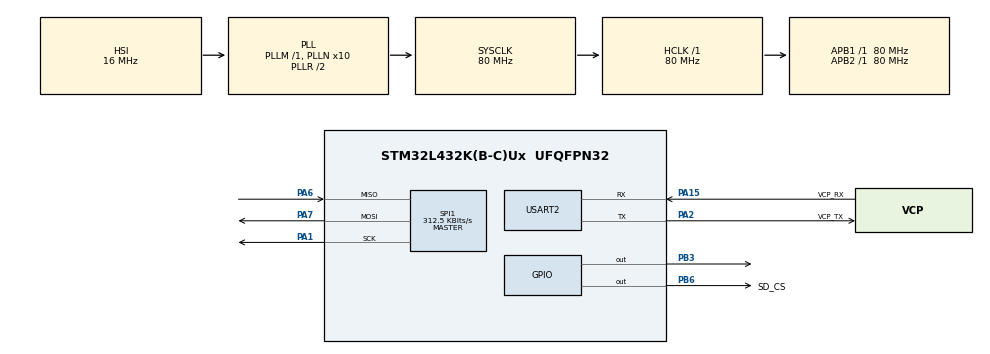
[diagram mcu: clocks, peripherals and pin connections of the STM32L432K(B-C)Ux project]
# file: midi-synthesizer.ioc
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Mcu.Family=STM32L4
Mcu.Name=STM32L432K(B-C)Ux
Mcu.Package=UFQFPN32
NUCLEO-L432KC.Bsp_Common_DEMO=true
NUCLEO-L432KC.LD3=true
NVIC.PriorityGroup=NVIC_PRIORITYGROUP_4
PA0.GPIO_Label=MCO [High speed clock in]
PA0.Signal=RCC_CK_IN
PA1.Mode=Full_Duplex_Master
PA1.Signal=SPI1_SCK
PA13\ (JTMS-SWDIO).GPIO_Label=SWDIO
PA13\ (JTMS-SWDIO).Signal=SYS_JTMS-SWDIO
PA14\ (JTCK-SWCLK).GPIO_Label=SWCLK
PA14\ (JTCK-SWCLK).Signal=SYS_JTCK-SWCLK
PA15\ (JTDI).GPIO_Label=VCP_RX
PA15\ (JTDI).Mode=Asynchronous
PA15\ (JTDI).Signal=USART2_RX
PA2.GPIO_Label=VCP_TX
PA2.Mode=Asynchronous
PA2.Signal=USART2_TX
PA6.Mode=Full_Duplex_Master
PA6.Signal=SPI1_MISO
PA7.Mode=Full_Duplex_Master
PA7.Signal=SPI1_MOSI
PB3\ (JTDO-TRACESWO).Signal=GPIO_Output
PB6.GPIO_Label=SD_CS
PB6.Signal=GPIO_Output
PC14-OSC32_IN\ (PC14).Signal=RCC_OSC32_IN
PC15-OSC32_OUT\ (PC15).Signal=RCC_OSC32_OUT
ProjectManager.HeapSize=0x200
ProjectManager.StackSize=0x400
ProjectManager.TargetToolchain=CMake
RCC.ADCFreq_Value=80000000
RCC.AHBFreq_Value=80000000
RCC.APB1Freq_Value=80000000
RCC.APB1TimFreq_Value=80000000
RCC.APB2Freq_Value=80000000
RCC.APB2TimFreq_Value=80000000
RCC.CortexFreq_Value=80000000
RCC.HCLKFreq_Value=80000000
RCC.HSE_VALUE=8000000
RCC.HSI16_VALUE=16000000
RCC.HSI48_VALUE=48000000
RCC.HSI_VALUE=16000000
RCC.LSE_VALUE=32768
RCC.MSI_VALUE=4000000
RCC.PLLMUL=RCC_PLLMUL_4
RCC.PLLN=10
RCC.PLLSAI1N=10
RCC.PLLSourceVirtual=RCC_PLLSOURCE_HSI
RCC.SYSCLKFreq_VALUE=80000000
RCC.SYSCLKSource=RCC_SYSCLKSOURCE_PLLCLK
RCC.USBFreq_Value=80000000
RCC.VCOOutputFreq_Value=160000000
SPI1.BaudRatePrescaler=SPI_BAUDRATEPRESCALER_256
SPI1.CalculateBaudRate=312.5 KBits/s
SPI1.DataSize=SPI_DATASIZE_8BIT
SPI1.Direction=SPI_DIRECTION_2LINES
SPI1.Mode=SPI_MODE_MASTER
SPI1.VirtualType=VM_MASTER
USART2.VirtualMode-Asynchronous=VM_ASYNC
VP_FATFS_VS_Generic.Mode=User_defined
VP_NUCLEO-L432KC_VS_BSP_COMMON.Mode=COMMON
board=NUCLEO-L432KC

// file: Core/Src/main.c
/* USER CODE BEGIN Header */
/**
  ******************************************************************************
  * @file           : main.c
  * @brief          : Main program body
  ******************************************************************************
  * @attention
  *
  * Copyright (c) 2026 STMicroelectronics.
  * All rights reserved.
  *
  * This software is licensed under terms that can be found in the LICENSE file
  * in the root directory of this software component.
  * If no LICENSE file comes with this software, it is provided AS-IS.
  *
  ******************************************************************************
  */
/* USER CODE END Header */
#include "main.h"
#include "fatfs.h"
#include "spi.h"
#include "usart.h"
#include "gpio.h"

/* USER CODE BEGIN Includes */
#include "SEGGER_RTT.h"
#include <stdio.h>
/* USER CODE END Includes */

void SystemClock_Config(void);

int main(void)
{

  /* MCU Configuration--------------------------------------------------------*/

  /* Reset of all peripherals, Initializes the Flash interface and the Systick. */
  HAL_Init();

  /* Configure the system clock */
  SystemClock_Config();

  /* Initialize all configured peripherals */
  MX_GPIO_Init();
  MX_SPI1_Init();
  MX_FATFS_Init();
  MX_USART2_UART_Init();
  /* USER CODE BEGIN 2 */
  SEGGER_RTT_Init();

  // Open FAT filesystem
  FATFS FatFs; //Fatfs handle
  FRESULT res;

  while ((res = f_mount(&FatFs, "", 1)) != FR_OK) { // 1=mount now
    fprintf(stderr, "f_mount error (%i)\r\n", res);
    HAL_Delay(100);
  }
  /* USER CODE END 2 */

  /* Initialize leds */
  BSP_LED_Init(LED_GREEN);

  /* USER CODE BEGIN BSP */

  /* -- Sample board code to switch on leds ---- */
  BSP_LED_On(LED_GREEN);

  /* USER CODE END BSP */

  /* Infinite loop */
  /* USER CODE BEGIN WHILE */
  while (1) {

    /* -- Sample board code to toggle leds ---- */
    BSP_LED_Toggle(LED_GREEN);

    /* USER CODE END WHILE */

  }
}

void SystemClock_Config(void)
{
  RCC_OscInitTypeDef RCC_OscInitStruct = {0};
  RCC_ClkInitTypeDef RCC_ClkInitStruct = {0};

  /** Configure the main internal regulator output voltage
  */
  if (HAL_PWREx_ControlVoltageScaling(PWR_REGULATOR_VOLTAGE_SCALE1) != HAL_OK)
  {
    Error_Handler();
  }

  /** Initializes the RCC Oscillators according to the specified parameters
  * in the RCC_OscInitTypeDef structure.
  */
  RCC_OscInitStruct.OscillatorType = RCC_OSCILLATORTYPE_HSI;
  RCC_OscInitStruct.HSIState = RCC_HSI_ON;
  RCC_OscInitStruct.HSICalibrationValue = RCC_HSICALIBRATION_DEFAULT;
  RCC_OscInitStruct.PLL.PLLState = RCC_PLL_ON;
  RCC_OscInitStruct.PLL.PLLSource = RCC_PLLSOURCE_HSI;
  RCC_OscInitStruct.PLL.PLLM = 1;
  RCC_OscInitStruct.PLL.PLLN = 10;
  RCC_OscInitStruct.PLL.PLLP = RCC_PLLP_DIV7;
  RCC_OscInitStruct.PLL.PLLQ = RCC_PLLQ_DIV2;
  RCC_OscInitStruct.PLL.PLLR = RCC_PLLR_DIV2;
  if (HAL_RCC_OscConfig(&RCC_OscInitStruct) != HAL_OK)
  {
    Error_Handler();
  }

  /** Initializes the CPU, AHB and APB buses clocks
  */
  RCC_ClkInitStruct.ClockType = RCC_CLOCKTYPE_HCLK|RCC_CLOCKTYPE_SYSCLK
                              |RCC_CLOCKTYPE_PCLK1|RCC_CLOCKTYPE_PCLK2;
  RCC_ClkInitStruct.SYSCLKSource = RCC_SYSCLKSOURCE_PLLCLK;
  RCC_ClkInitStruct.AHBCLKDivider = RCC_SYSCLK_DIV1;
  RCC_ClkInitStruct.APB1CLKDivider = RCC_HCLK_DIV1;
  RCC_ClkInitStruct.APB2CLKDivider = RCC_HCLK_DIV1;

  if (HAL_RCC_ClockConfig(&RCC_ClkInitStruct, FLASH_LATENCY_4) != HAL_OK)
  {
    Error_Handler();
  }
}

void Error_Handler(void)
{
  __disable_irq();
  while (1)
  {
  }
}
